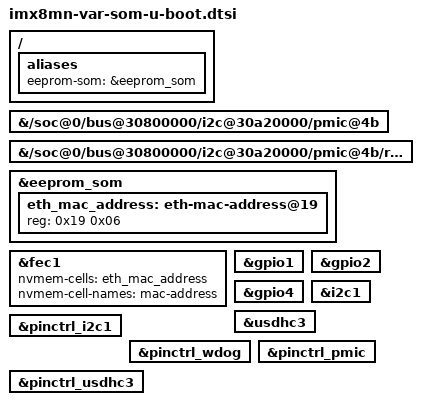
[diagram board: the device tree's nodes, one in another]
// SPDX-License-Identifier: GPL-2.0+
/*
 * Copyright 2025 Dimonoff
 */

#include "imx8mn-u-boot.dtsi"

/ {
	aliases {
		eeprom-som = &eeprom_som;
	};
};

&{/soc@0/bus@30800000/i2c@30a20000/pmic@4b} {
	bootph-pre-ram;
};

&{/soc@0/bus@30800000/i2c@30a20000/pmic@4b/regulators} {
	bootph-pre-ram;
};

&eeprom_som {
	bootph-all;
	#address-cells = <1>;
	#size-cells = <1>;
	eth_mac_address: eth-mac-address@19 {
		reg = <0x19 0x06>;
	};
};

&fec1 {
	nvmem-cells = <&eth_mac_address>;
	nvmem-cell-names = "mac-address";
};

&gpio1 {
	bootph-pre-ram;
};

&gpio2 {
	bootph-pre-ram;
};

&gpio4 {
	bootph-pre-ram;
};

&i2c1 {
	bootph-all;
};

&usdhc3 {
	bootph-pre-ram;
};

&pinctrl_i2c1 {
	bootph-all;
};

&pinctrl_wdog {
	bootph-pre-ram;
};

&pinctrl_pmic {
	bootph-pre-ram;
};

&pinctrl_usdhc3 {
	bootph-pre-ram;
};
